VERSION ""

NS_ :

BS_:

BU_: VCU TFD_Redundant TFD_Main
VAL_TABLE_ Steering_Mode 2 "wheel vibrations" 1 "normal mode" 0 "demo code" ;
VAL_TABLE_ Detent_Mode 3 "Bumpless" 2 "Closest to Center" 1 "Center" 0 "None" ;
VAL_TABLE_ Set_Param_Values 256 "Set Center Zero Position" 274 "Transmit Rate in milliseconds (5-200) (for 20Hz send 0x32)" 273 "Set Turns lock to lock (2-8, gain = 30, for 4 send 0x78)" 272 "Send Endstop brake gain (50-100)" ;
VAL_TABLE_ Get_Param_Values 510 "Software Version" 274 "Transmit Rate" 273 "Turns lock to lock" 272 "Endstop brake gain" ;

BO_ 3221225472 VECTOR__INDEPENDENT_SIG_MSG: 0 Vector__XXX
 SG_ Set_Parameter_Index : 0|9@0+ (1,0) [0|511] "" Vector__XXX

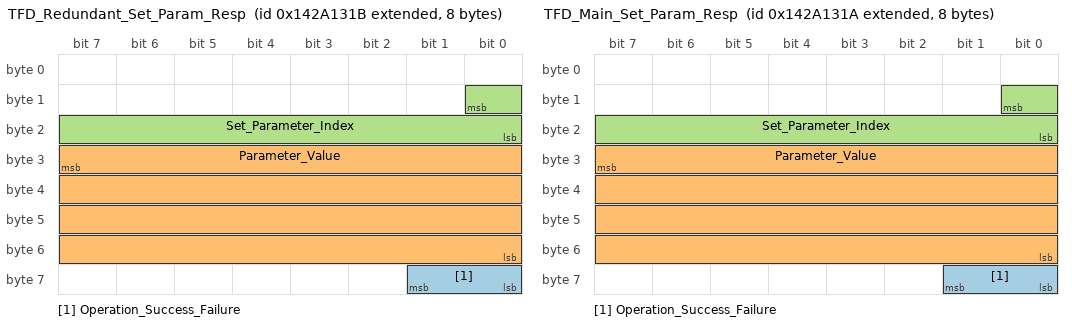
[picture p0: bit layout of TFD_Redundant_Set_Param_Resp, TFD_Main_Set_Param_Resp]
BO_ 2485785371 TFD_Redundant_Set_Param_Resp: 8 TFD_Redundant
 SG_ Operation_Success_Failure : 57|2@0+ (1,0) [0|3] "" Vector__XXX
 SG_ Parameter_Value : 31|32@0+ (1,0) [0|4294967295] "" Vector__XXX
 SG_ Set_Parameter_Index : 8|9@0+ (1,0) [0|511] "" Vector__XXX

BO_ 2485721875 VCU_TFD_Redundant_Set_Param: 8 VCU
 SG_ Parameter_Value : 31|32@0+ (1,0) [0|4294967295] ""  TFD_Redundant
 SG_ Set_Parameter_Index : 8|9@0+ (1,0) [0|511] ""  TFD_Redundant

BO_ 2485654299 TFD_Redundant_Get_Param_Resp: 8 TFD_Redundant
 SG_ Get_Parameter_Index : 8|9@0+ (1,0) [0|511] ""  VCU
 SG_ Parameter_Value : 31|32@0+ (1,0) [0|4294967295] ""  VCU

BO_ 2485590803 VCU_TFD_Redundant_Get_Param: 4 VCU
 SG_ Get_Parameter_Index : 8|9@0+ (1,0) [0|511] ""  TFD_Redundant

BO_ 2485785370 TFD_Main_Set_Param_Resp: 8 TFD_Main
 SG_ Operation_Success_Failure : 57|2@0+ (1,0) [0|3] "" Vector__XXX
 SG_ Parameter_Value : 31|32@0+ (1,0) [0|4294967295] "" Vector__XXX
 SG_ Set_Parameter_Index : 8|9@0+ (1,0) [0|511] "" Vector__XXX

BO_ 2485721619 VCU_TFD_Main_Set_Param: 8 VCU
 SG_ Parameter_Value : 31|32@0+ (1,0) [0|4294967295] ""  TFD_Main
 SG_ Set_Parameter_Index : 8|9@0+ (1,0) [0|511] ""  TFD_Main

BO_ 2485654298 TFD_Main_Get_Param_Resp: 8 TFD_Main
 SG_ Get_Parameter_Index : 8|9@0+ (1,0) [0|511] ""  VCU
 SG_ Parameter_Value : 31|32@0+ (1,0) [0|4294967295] ""  VCU

BO_ 2485590547 VCU_TFD_Main_Get_Param: 4 VCU
 SG_ Get_Parameter_Index : 8|9@0+ (1,0) [0|511] ""  TFD_Main

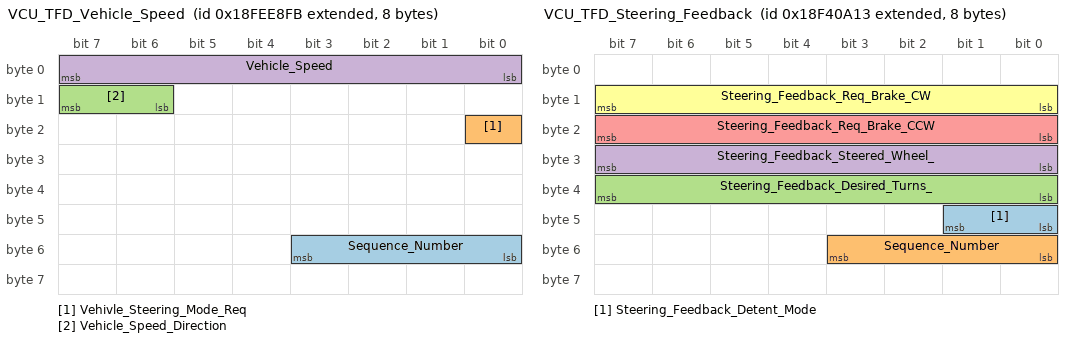
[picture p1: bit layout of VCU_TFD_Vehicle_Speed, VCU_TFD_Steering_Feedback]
BO_ 2566842619 VCU_TFD_Vehicle_Speed: 8 VCU
 SG_ Sequence_Number : 51|4@0+ (1,0) [0|15] ""  TFD_Redundant,TFD_Main
 SG_ Vehivle_Steering_Mode_Req : 16|1@0+ (1,0) [0|1] ""  TFD_Redundant,TFD_Main
 SG_ Vehicle_Speed_Direction : 15|2@0+ (1,0) [0|3] ""  TFD_Redundant,TFD_Main
 SG_ Vehicle_Speed : 7|8@0+ (1,0) [0|255] "kph"  TFD_Redundant,TFD_Main

BO_ 2566130195 VCU_TFD_Steering_Feedback: 8 VCU
 SG_ Steering_Feedback_Detent_Mode : 41|2@0+ (1,0) [0|3] ""  TFD_Redundant,TFD_Main
 SG_ Sequence_Number : 51|4@0+ (1,0) [0|15] ""  TFD_Redundant,TFD_Main
 SG_ Steering_Feedback_Desired_Turns_ : 39|8@0+ (0.033333,0) [0|8.499915] ""  TFD_Redundant,TFD_Main
 SG_ Steering_Feedback_Steered_Wheel_ : 31|8@0- (1,0) [-128|127] "%"  TFD_Redundant,TFD_Main
 SG_ Steering_Feedback_Req_Brake_CCW : 23|8@0+ (1,0) [0|255] "%"  TFD_Redundant,TFD_Main
 SG_ Steering_Feedback_Req_Brake_CW : 15|8@0+ (1,0) [0|255] "%"  TFD_Redundant,TFD_Main

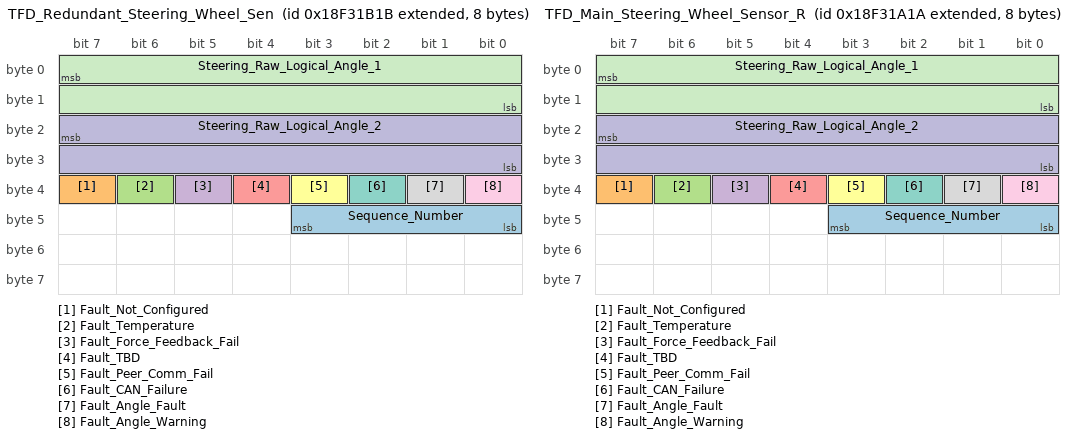
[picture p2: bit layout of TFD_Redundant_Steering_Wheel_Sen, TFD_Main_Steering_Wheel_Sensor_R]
BO_ 2566069019 TFD_Redundant_Steering_Wheel_Sen: 8 TFD_Redundant
 SG_ Sequence_Number : 43|4@0+ (1,0) [0|15] ""  VCU
 SG_ Fault_Not_Configured : 39|1@1+ (1,0) [0|1] ""  VCU
 SG_ Fault_Temperature : 38|1@1+ (1,0) [0|1] ""  VCU
 SG_ Fault_Force_Feedback_Fail : 37|1@1+ (1,0) [0|1] ""  VCU
 SG_ Fault_TBD : 36|1@1+ (1,0) [0|1] ""  VCU
 SG_ Fault_Peer_Comm_Fail : 35|1@1+ (1,0) [0|1] ""  VCU
 SG_ Fault_CAN_Failure : 34|1@1+ (1,0) [0|1] ""  VCU
 SG_ Fault_Angle_Fault : 33|1@1+ (1,0) [0|1] ""  VCU
 SG_ Fault_Angle_Warning : 32|1@1+ (1,0) [0|1] ""  VCU
 SG_ Steering_Raw_Logical_Angle_2 : 23|16@0- (0.087890625,0) [-2880|2879.912109375] ""  VCU
 SG_ Steering_Raw_Logical_Angle_1 : 7|16@0- (0.087890625,0) [-2880|2879.912109375] ""  VCU

BO_ 2566068762 TFD_Main_Steering_Wheel_Sensor_R: 8 TFD_Main
 SG_ Sequence_Number : 43|4@0+ (1,0) [0|15] ""  VCU
 SG_ Fault_Not_Configured : 39|1@1+ (1,0) [0|1] ""  VCU
 SG_ Fault_Temperature : 38|1@1+ (1,0) [0|1] ""  VCU
 SG_ Fault_Force_Feedback_Fail : 37|1@1+ (1,0) [0|1] ""  VCU
 SG_ Fault_TBD : 36|1@1+ (1,0) [0|1] ""  VCU
 SG_ Fault_Peer_Comm_Fail : 35|1@1+ (1,0) [0|1] ""  VCU
 SG_ Fault_CAN_Failure : 34|1@1+ (1,0) [0|1] ""  VCU
 SG_ Fault_Angle_Fault : 33|1@1+ (1,0) [0|1] ""  VCU
 SG_ Fault_Angle_Warning : 32|1@1+ (1,0) [0|1] ""  VCU
 SG_ Steering_Raw_Logical_Angle_2 : 23|16@0- (0.087890625,0) [-2880|2879.912109375] ""  VCU
 SG_ Steering_Raw_Logical_Angle_1 : 7|16@0- (0.087890625,0) [-2880|2879.912109375] ""  VCU

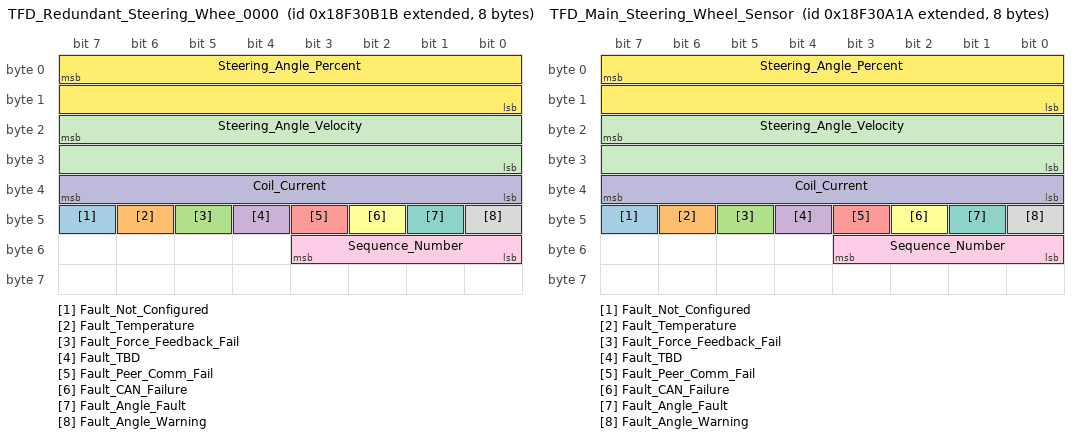
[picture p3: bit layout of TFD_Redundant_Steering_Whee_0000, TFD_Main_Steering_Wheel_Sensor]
BO_ 2566064923 TFD_Redundant_Steering_Whee_0000: 8 TFD_Redundant
 SG_ Fault_Not_Configured : 47|1@1+ (1,0) [0|1] ""  VCU
 SG_ Fault_Temperature : 46|1@1+ (1,0) [0|1] ""  VCU
 SG_ Fault_Force_Feedback_Fail : 45|1@1+ (1,0) [0|1] ""  VCU
 SG_ Fault_TBD : 44|1@1+ (1,0) [0|1] ""  VCU
 SG_ Fault_Peer_Comm_Fail : 43|1@1+ (1,0) [0|1] ""  VCU
 SG_ Fault_CAN_Failure : 42|1@1+ (1,0) [0|1] ""  VCU
 SG_ Fault_Angle_Fault : 41|1@1+ (1,0) [0|1] ""  VCU
 SG_ Fault_Angle_Warning : 40|1@1+ (1,0) [0|1] ""  VCU
 SG_ Sequence_Number : 51|4@0+ (1,0) [0|15] ""  VCU
 SG_ Coil_Current : 32|8@1+ (0.125,0) [0|31.875] "mA"  VCU
 SG_ Steering_Angle_Velocity : 23|16@0- (0.0146484375,-300) [-600|600] "rpm"  VCU
 SG_ Steering_Angle_Percent : 7|16@0- (0.01,0) [-327.68|327.67] "%"  VCU

BO_ 2566064666 TFD_Main_Steering_Wheel_Sensor: 8 TFD_Main
 SG_ Fault_Not_Configured : 47|1@1+ (1,0) [0|1] ""  VCU
 SG_ Fault_Temperature : 46|1@1+ (1,0) [0|1] ""  VCU
 SG_ Fault_Force_Feedback_Fail : 45|1@1+ (1,0) [0|1] ""  VCU
 SG_ Fault_TBD : 44|1@1+ (1,0) [0|1] ""  VCU
 SG_ Fault_Peer_Comm_Fail : 43|1@1+ (1,0) [0|1] ""  VCU
 SG_ Fault_CAN_Failure : 42|1@1+ (1,0) [0|1] ""  VCU
 SG_ Fault_Angle_Fault : 41|1@1+ (1,0) [0|1] ""  VCU
 SG_ Fault_Angle_Warning : 40|1@1+ (1,0) [0|1] ""  VCU
 SG_ Sequence_Number : 51|4@0+ (1,0) [0|15] ""  VCU
 SG_ Coil_Current : 32|8@1+ (0.125,0) [0|31.875] "mA"  VCU
 SG_ Steering_Angle_Velocity : 23|16@0- (0.0146484375,-300) [-600|600] "rpm"  VCU
 SG_ Steering_Angle_Percent : 7|16@0- (0.01,0) [-327.68|327.67] "%"  VCU

CM_ BO_ 3221225472 "This is a message for not used signals, created by Vector CANdb++ DBC OLE DB Provider.";
CM_ SG_ 2566842619 Vehicle_Speed_Direction "Reserved";
CM_ SG_ 2566130195 Steering_Feedback_Detent_Mode "Updates to the steering wheel position (sections 5.1.1 and 5.3.1) occur on transition back to detent mode “none”.";
CM_ SG_ 2566130195 Steering_Feedback_Desired_Turns_ "This parameter contains the number of turns lock to lock that the vehicle is requesting the TFD to use for calculating end stop position and wheel percent. If this value is out of bounds or equal to 0xFF, the value stored in EEPROM is used";
BA_DEF_ BU_  "NmStationAddress" HEX 0 0;
BA_DEF_ BO_  "GenMsgCycleTime" INT 0 3600000;
BA_DEF_ BO_  "GenMsgSendType" ENUM  "cyclic","reserved","cyclicIfActive","IfActive","reserved","reserved","reserved","reserved","reserved","noMsgSendType";
BA_DEF_  "BusType" STRING ;
BA_DEF_ SG_  "SystemSignalLongSymbol" STRING ;
BA_DEF_ BO_  "SystemMessageLongSymbol" STRING ;
BA_DEF_DEF_  "NmStationAddress" 0;
BA_DEF_DEF_  "GenMsgCycleTime" 0;
BA_DEF_DEF_  "GenMsgSendType" "cyclic";
BA_DEF_DEF_  "BusType" "CAN";
BA_DEF_DEF_  "SystemSignalLongSymbol" "";
BA_DEF_DEF_  "SystemMessageLongSymbol" "";
BA_ "NmStationAddress" BU_ VCU 19;
BA_ "NmStationAddress" BU_ TFD_Redundant 27;
BA_ "NmStationAddress" BU_ TFD_Main 26;
BA_ "GenMsgSendType" BO_ 2485785371 3;
BA_ "GenMsgSendType" BO_ 2485721875 3;
BA_ "GenMsgSendType" BO_ 2485654299 3;
BA_ "GenMsgSendType" BO_ 2485590803 3;
BA_ "GenMsgSendType" BO_ 2485785370 3;
BA_ "GenMsgSendType" BO_ 2485721619 3;
BA_ "GenMsgSendType" BO_ 2485654298 3;
BA_ "GenMsgSendType" BO_ 2485590547 3;
BA_ "GenMsgCycleTime" BO_ 2566842619 50;
BA_ "GenMsgCycleTime" BO_ 2566130195 50;
BA_ "GenMsgCycleTime" BO_ 2566069019 50;
BA_ "SystemMessageLongSymbol" BO_ 2566069019 "TFD_Redundant_Steering_Wheel_Sensor_Raw";
BA_ "GenMsgCycleTime" BO_ 2566068762 50;
BA_ "SystemMessageLongSymbol" BO_ 2566068762 "TFD_Main_Steering_Wheel_Sensor_Raw";
BA_ "SystemMessageLongSymbol" BO_ 2566064923 "TFD_Redundant_Steering_Wheel_Sensor";
BA_ "GenMsgCycleTime" BO_ 2566064666 50;
BA_ "SystemSignalLongSymbol" SG_ 2566130195 Steering_Feedback_Desired_Turns_ "Steering_Feedback_Desired_Turns_To_Lock";
BA_ "SystemSignalLongSymbol" SG_ 2566130195 Steering_Feedback_Steered_Wheel_ "Steering_Feedback_Steered_Wheel_Perc";
VAL_ 3221225472 Set_Parameter_Index 256 "Set Center Zero Position" 274 "Transmit Rate in milliseconds (5-200) (for 20Hz send 0x32)" 273 "Set Turns lock to lock (2-8, gain = 30, for 4 send 0x78)" 272 "Send Endstop brake gain (50-100)" ;
VAL_ 2485785371 Set_Parameter_Index 256 "Set Center Zero Position" 274 "Transmit Rate in milliseconds (5-200) (for 20Hz send 0x32)" 273 "Set Turns lock to lock (2-8, gain = 30, for 4 send 0x78)" 272 "Send Endstop brake gain (50-100)" ;
VAL_ 2485721875 Set_Parameter_Index 256 "Set Center Zero Position" 274 "Transmit Rate in milliseconds (5-200) (for 20Hz send 0x32)" 273 "Set Turns lock to lock (2-8, gain = 30, for 4 send 0x78)" 272 "Send Endstop brake gain (50-100)" ;
VAL_ 2485654299 Get_Parameter_Index 510 "Software Version" 274 "Transmit Rate" 273 "Turns lock to lock" 272 "Endstop brake gain" ;
VAL_ 2485590803 Get_Parameter_Index 510 "Software Version" 274 "Transmit Rate" 273 "Turns lock to lock" 272 "Endstop brake gain" ;
VAL_ 2485785370 Set_Parameter_Index 256 "Set Center Zero Position" 274 "Transmit Rate in milliseconds (5-200) (for 20Hz send 0x32)" 273 "Set Turns lock to lock (2-8, gain = 30, for 4 send 0x78)" 272 "Send Endstop brake gain (50-100)" ;
VAL_ 2485721619 Set_Parameter_Index 256 "Set Center Zero Position" 274 "Transmit Rate in milliseconds (5-200) (for 20Hz send 0x32)" 273 "Set Turns lock to lock (2-8, gain = 30, for 4 send 0x78)" 272 "Send Endstop brake gain (50-100)" ;
VAL_ 2485654298 Get_Parameter_Index 510 "Software Version" 274 "Transmit Rate" 273 "Turns lock to lock" 272 "Endstop brake gain" ;
VAL_ 2485590547 Get_Parameter_Index 510 "Software Version" 274 "Transmit Rate" 273 "Turns lock to lock" 272 "Endstop brake gain" ;
VAL_ 2566130195 Steering_Feedback_Detent_Mode 3 "Bumpless" 2 "Closest to Center" 1 "Center" 0 "None" ;
